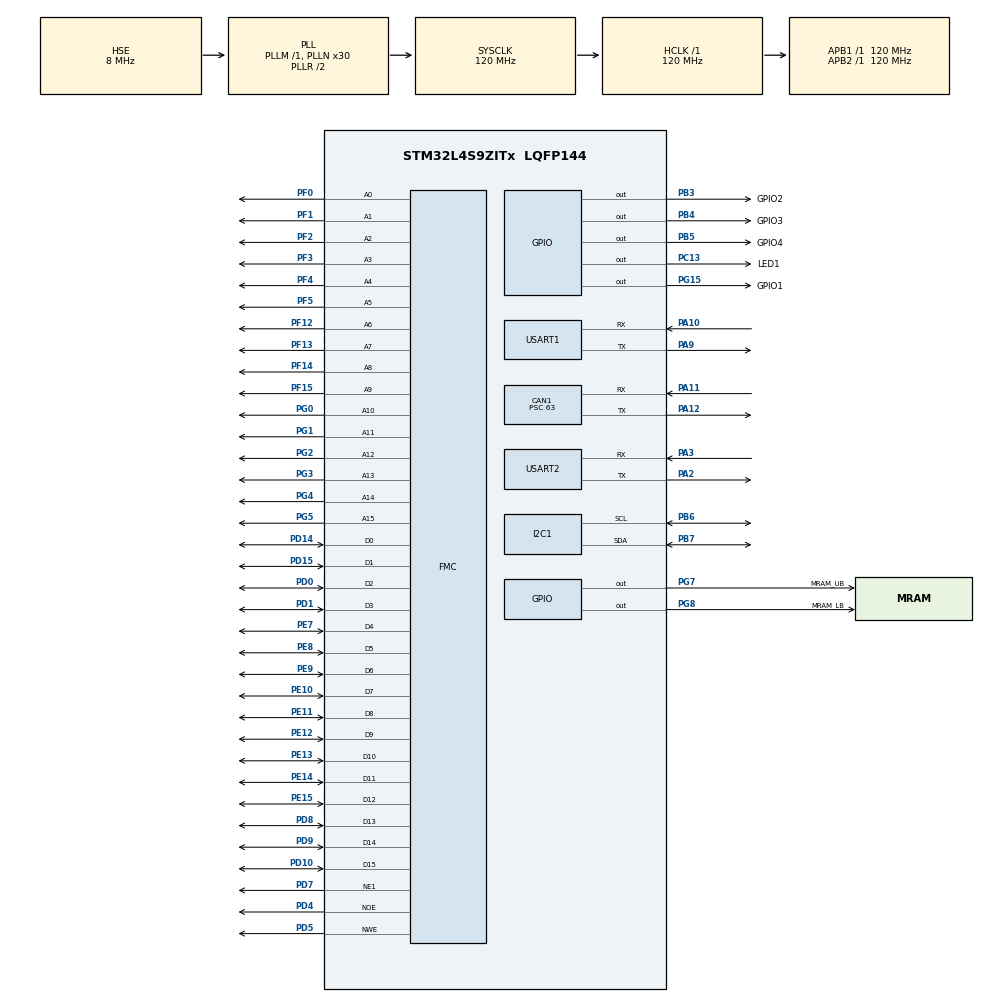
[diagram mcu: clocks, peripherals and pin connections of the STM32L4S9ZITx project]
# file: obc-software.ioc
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CAN1.BS1=CAN_BS1_1TQ
CAN1.BS2=CAN_BS2_1TQ
CAN1.CalculateTimeQuantum=525.0
CAN1.Prescaler=63
FMC.WriteFifo1=FMC_WRITE_FIFO_DISABLE
FMC.WriteOperation1=FMC_WRITE_OPERATION_ENABLE
I2C1.Timing=0x307075B1
Mcu.Family=STM32L4
Mcu.Name=STM32L4S9ZITx
Mcu.Package=LQFP144
NVIC.PriorityGroup=NVIC_PRIORITYGROUP_4
PA10.Mode=Asynchronous
PA10.Signal=USART1_RX
PA11.Mode=Master
PA11.Signal=CAN1_RX
PA12.Mode=Master
PA12.Signal=CAN1_TX
PA13\ (JTMS/SWDIO).Mode=Serial_Wire
PA13\ (JTMS/SWDIO).Signal=SYS_JTMS-SWDIO
PA14\ (JTCK/SWCLK).Mode=Serial_Wire
PA14\ (JTCK/SWCLK).Signal=SYS_JTCK-SWCLK
PA2.Mode=Asynchronous
PA2.Signal=USART2_TX
PA3.Mode=Asynchronous
PA3.Signal=USART2_RX
PA9.Mode=Asynchronous
PA9.Signal=USART1_TX
PB3\ (JTDO/TRACESWO).GPIO_Label=GPIO2
PB3\ (JTDO/TRACESWO).Signal=GPIO_Output
PB4\ (NJTRST).GPIO_Label=GPIO3
PB4\ (NJTRST).Signal=GPIO_Output
PB5.GPIO_Label=GPIO4
PB5.Signal=GPIO_Output
PB6.Mode=I2C
PB6.Signal=I2C1_SCL
PB7.Mode=I2C
PB7.Signal=I2C1_SDA
PC13.GPIO_Label=LED1
PC13.Signal=GPIO_Output
PD0.Signal=FMC_D2_DA2
PD1.Signal=FMC_D3_DA3
PD10.Signal=FMC_D15_DA15
PD14.Signal=FMC_D0_DA0
PD15.Signal=FMC_D1_DA1
PD4.Signal=FMC_NOE
PD5.Signal=FMC_NWE
PD7.Mode=NorPsramChipSelect1_1
PD7.Signal=FMC_NE1
PD8.Signal=FMC_D13_DA13
PD9.Signal=FMC_D14_DA14
PE10.Signal=FMC_D7_DA7
PE11.Signal=FMC_D8_DA8
PE12.Signal=FMC_D9_DA9
PE13.Signal=FMC_D10_DA10
PE14.Signal=FMC_D11_DA11
PE15.Signal=FMC_D12_DA12
PE7.Signal=FMC_D4_DA4
PE8.Signal=FMC_D5_DA5
PE9.Signal=FMC_D6_DA6
PF0.Signal=FMC_A0
PF1.Signal=FMC_A1
PF12.Signal=FMC_A6
PF13.Signal=FMC_A7
PF14.Signal=FMC_A8
PF15.Signal=FMC_A9
PF2.Signal=FMC_A2
PF3.Signal=FMC_A3
PF4.Signal=FMC_A4
PF5.Signal=FMC_A5
PG0.Signal=FMC_A10
PG1.Signal=FMC_A11
PG15.GPIO_Label=GPIO1
PG15.Signal=GPIO_Output
PG2.Signal=FMC_A12
PG3.Signal=FMC_A13
PG4.Signal=FMC_A14
PG5.Signal=FMC_A15
PG7.GPIO_Label=MRAM_UB
PG7.Signal=GPIO_Output
PG8.GPIO_Label=MRAM_LB
PG8.Signal=GPIO_Output
PH0-OSC_IN\ (PH0).Mode=HSE-External-Oscillator
PH0-OSC_IN\ (PH0).Signal=RCC_OSC_IN
PH1-OSC_OUT\ (PH1).Mode=HSE-External-Oscillator
PH1-OSC_OUT\ (PH1).Signal=RCC_OSC_OUT
ProjectManager.HeapSize=0x200
ProjectManager.StackSize=0x400
ProjectManager.TargetToolchain=SW4STM32
RCC.ADCFreq_Value=32000000
RCC.AHBFreq_Value=120000000
RCC.APB1Freq_Value=120000000
RCC.APB1TimFreq_Value=120000000
RCC.APB2Freq_Value=120000000
RCC.APB2TimFreq_Value=120000000
RCC.CortexFreq_Value=120000000
RCC.HCLKFreq_Value=120000000
RCC.HSE_VALUE=8000000
RCC.HSI48_VALUE=48000000
RCC.HSI_VALUE=16000000
RCC.LSE_VALUE=32768
RCC.MSI_VALUE=4000000
RCC.PLLN=30
RCC.PLLSourceVirtual=RCC_PLLSOURCE_HSE
RCC.SYSCLKFreq_VALUE=120000000
RCC.SYSCLKSource=RCC_SYSCLKSOURCE_PLLCLK
RCC.USBFreq_Value=32000000
RCC.VCOOutputFreq_Value=240000000
SH.FMC_A0.0=FMC_A0,16b-a1
SH.FMC_A1.0=FMC_A1,16b-a1
SH.FMC_A10.0=FMC_A10,16b-a1
SH.FMC_A11.0=FMC_A11,16b-a1
SH.FMC_A12.0=FMC_A12,16b-a1
SH.FMC_A13.0=FMC_A13,16b-a1
SH.FMC_A14.0=FMC_A14,16b-a1
SH.FMC_A15.0=FMC_A15,16b-a1
SH.FMC_A2.0=FMC_A2,16b-a1
SH.FMC_A3.0=FMC_A3,16b-a1
SH.FMC_A4.0=FMC_A4,16b-a1
SH.FMC_A5.0=FMC_A5,16b-a1
SH.FMC_A6.0=FMC_A6,16b-a1
SH.FMC_A7.0=FMC_A7,16b-a1
SH.FMC_A8.0=FMC_A8,16b-a1
SH.FMC_A9.0=FMC_A9,16b-a1
SH.FMC_D0_DA0.0=FMC_D0,16b-d1
SH.FMC_D10_DA10.0=FMC_D10,16b-d1
SH.FMC_D11_DA11.0=FMC_D11,16b-d1
SH.FMC_D12_DA12.0=FMC_D12,16b-d1
SH.FMC_D13_DA13.0=FMC_D13,16b-d1
SH.FMC_D14_DA14.0=FMC_D14,16b-d1
SH.FMC_D15_DA15.0=FMC_D15,16b-d1
SH.FMC_D1_DA1.0=FMC_D1,16b-d1
SH.FMC_D2_DA2.0=FMC_D2,16b-d1
SH.FMC_D3_DA3.0=FMC_D3,16b-d1
SH.FMC_D4_DA4.0=FMC_D4,16b-d1
SH.FMC_D5_DA5.0=FMC_D5,16b-d1
SH.FMC_D6_DA6.0=FMC_D6,16b-d1
SH.FMC_D7_DA7.0=FMC_D7,16b-d1
SH.FMC_D8_DA8.0=FMC_D8,16b-d1
SH.FMC_D9_DA9.0=FMC_D9,16b-d1
SH.FMC_NOE.0=FMC_NOE,Sram1
SH.FMC_NWE.0=FMC_NWE,Sram1
USART1.VirtualMode-Asynchronous=VM_ASYNC
USART2.VirtualMode-Asynchronous=VM_ASYNC
board=custom

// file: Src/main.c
/* USER CODE BEGIN Header */
/**
  ******************************************************************************
  * @file           : main.c
  * @brief          : Main program body
  ******************************************************************************
  * @attention
  *
  * <h2><center>&copy; Copyright (c) 2019 STMicroelectronics.
  * All rights reserved.</center></h2>
  *
  * This software component is licensed by ST under BSD 3-Clause license,
  * the "License"; You may not use this file except in compliance with the
  * License. You may obtain a copy of the License at:
  *                        opensource.org/licenses/BSD-3-Clause
  *
  ******************************************************************************
  */
/* USER CODE END Header */

#include "main.h"

/* USER CODE BEGIN Includes */
#include "string.h"
/* USER CODE END Includes */

CAN_HandleTypeDef hcan1;

I2C_HandleTypeDef hi2c1;

UART_HandleTypeDef huart1;
UART_HandleTypeDef huart2;

SRAM_HandleTypeDef hsram1;

/* USER CODE BEGIN PV */
volatile __attribute__((section (".mram"))) char mramData[150];
/* USER CODE END PV */

void SystemClock_Config(void);
static void MX_GPIO_Init(void);
static void MX_USART1_UART_Init(void);
static void MX_CAN1_Init(void);
static void MX_FMC_Init(void);
static void MX_I2C1_Init(void);
static void MX_USART2_UART_Init(void);

int main(void)
{

  /* MCU Configuration--------------------------------------------------------*/

  /* Reset of all peripherals, Initializes the Flash interface and the Systick. */
  HAL_Init();

  /* Configure the system clock */
  SystemClock_Config();

  /* Initialize all configured peripherals */
  MX_GPIO_Init();
  MX_USART1_UART_Init();
  MX_CAN1_Init();
  MX_FMC_Init();
  MX_I2C1_Init();
  MX_USART2_UART_Init();
  /* USER CODE BEGIN 2 */
    HAL_SRAM_WriteOperation_Enable(&hsram1);
  /* USER CODE END 2 */

  /* Infinite loop */
  /* USER CODE BEGIN WHILE */
  main_cpp();
    /* USER CODE END WHILE */

}

void SystemClock_Config(void)
{
  RCC_OscInitTypeDef RCC_OscInitStruct = {0};
  RCC_ClkInitTypeDef RCC_ClkInitStruct = {0};
  RCC_PeriphCLKInitTypeDef PeriphClkInit = {0};

  /** Configure the main internal regulator output voltage
  */
  if (HAL_PWREx_ControlVoltageScaling(PWR_REGULATOR_VOLTAGE_SCALE1_BOOST) != HAL_OK)
  {
    Error_Handler();
  }
  /** Initializes the CPU, AHB and APB busses clocks
  */
  RCC_OscInitStruct.OscillatorType = RCC_OSCILLATORTYPE_HSE;
  RCC_OscInitStruct.HSEState = RCC_HSE_ON;
  RCC_OscInitStruct.PLL.PLLState = RCC_PLL_ON;
  RCC_OscInitStruct.PLL.PLLSource = RCC_PLLSOURCE_HSE;
  RCC_OscInitStruct.PLL.PLLM = 1;
  RCC_OscInitStruct.PLL.PLLN = 30;
  RCC_OscInitStruct.PLL.PLLP = RCC_PLLP_DIV2;
  RCC_OscInitStruct.PLL.PLLQ = RCC_PLLQ_DIV2;
  RCC_OscInitStruct.PLL.PLLR = RCC_PLLR_DIV2;
  if (HAL_RCC_OscConfig(&RCC_OscInitStruct) != HAL_OK)
  {
    Error_Handler();
  }
  /** Initializes the CPU, AHB and APB busses clocks
  */
  RCC_ClkInitStruct.ClockType = RCC_CLOCKTYPE_HCLK|RCC_CLOCKTYPE_SYSCLK
                              |RCC_CLOCKTYPE_PCLK1|RCC_CLOCKTYPE_PCLK2;
  RCC_ClkInitStruct.SYSCLKSource = RCC_SYSCLKSOURCE_PLLCLK;
  RCC_ClkInitStruct.AHBCLKDivider = RCC_SYSCLK_DIV1;
  RCC_ClkInitStruct.APB1CLKDivider = RCC_HCLK_DIV1;
  RCC_ClkInitStruct.APB2CLKDivider = RCC_HCLK_DIV1;

  if (HAL_RCC_ClockConfig(&RCC_ClkInitStruct, FLASH_LATENCY_5) != HAL_OK)
  {
    Error_Handler();
  }
  PeriphClkInit.PeriphClockSelection = RCC_PERIPHCLK_USART1|RCC_PERIPHCLK_USART2
                              |RCC_PERIPHCLK_I2C1;
  PeriphClkInit.Usart1ClockSelection = RCC_USART1CLKSOURCE_PCLK2;
  PeriphClkInit.Usart2ClockSelection = RCC_USART2CLKSOURCE_PCLK1;
  PeriphClkInit.I2c1ClockSelection = RCC_I2C1CLKSOURCE_PCLK1;
  if (HAL_RCCEx_PeriphCLKConfig(&PeriphClkInit) != HAL_OK)
  {
    Error_Handler();
  }
}

static void MX_CAN1_Init(void)
{

  hcan1.Instance = CAN1;
  hcan1.Init.Prescaler = 63;
  hcan1.Init.Mode = CAN_MODE_NORMAL;
  hcan1.Init.SyncJumpWidth = CAN_SJW_1TQ;
  hcan1.Init.TimeSeg1 = CAN_BS1_1TQ;
  hcan1.Init.TimeSeg2 = CAN_BS2_1TQ;
  hcan1.Init.TimeTriggeredMode = DISABLE;
  hcan1.Init.AutoBusOff = DISABLE;
  hcan1.Init.AutoWakeUp = DISABLE;
  hcan1.Init.AutoRetransmission = DISABLE;
  hcan1.Init.ReceiveFifoLocked = DISABLE;
  hcan1.Init.TransmitFifoPriority = DISABLE;
  if (HAL_CAN_Init(&hcan1) != HAL_OK)
  {
    Error_Handler();
  }

}

static void MX_I2C1_Init(void)
{

  hi2c1.Instance = I2C1;
  hi2c1.Init.Timing = 0x307075B1;
  hi2c1.Init.OwnAddress1 = 0;
  hi2c1.Init.AddressingMode = I2C_ADDRESSINGMODE_7BIT;
  hi2c1.Init.DualAddressMode = I2C_DUALADDRESS_DISABLE;
  hi2c1.Init.OwnAddress2 = 0;
  hi2c1.Init.OwnAddress2Masks = I2C_OA2_NOMASK;
  hi2c1.Init.GeneralCallMode = I2C_GENERALCALL_DISABLE;
  hi2c1.Init.NoStretchMode = I2C_NOSTRETCH_DISABLE;
  if (HAL_I2C_Init(&hi2c1) != HAL_OK)
  {
    Error_Handler();
  }
  /** Configure Analogue filter
  */
  if (HAL_I2CEx_ConfigAnalogFilter(&hi2c1, I2C_ANALOGFILTER_ENABLE) != HAL_OK)
  {
    Error_Handler();
  }
  /** Configure Digital filter
  */
  if (HAL_I2CEx_ConfigDigitalFilter(&hi2c1, 0) != HAL_OK)
  {
    Error_Handler();
  }

}

static void MX_USART1_UART_Init(void)
{

  huart1.Instance = USART1;
  huart1.Init.BaudRate = 115200;
  huart1.Init.WordLength = UART_WORDLENGTH_8B;
  huart1.Init.StopBits = UART_STOPBITS_1;
  huart1.Init.Parity = UART_PARITY_NONE;
  huart1.Init.Mode = UART_MODE_TX_RX;
  huart1.Init.HwFlowCtl = UART_HWCONTROL_NONE;
  huart1.Init.OverSampling = UART_OVERSAMPLING_16;
  huart1.Init.OneBitSampling = UART_ONE_BIT_SAMPLE_DISABLE;
  huart1.Init.ClockPrescaler = UART_PRESCALER_DIV1;
  huart1.AdvancedInit.AdvFeatureInit = UART_ADVFEATURE_NO_INIT;
  if (HAL_UART_Init(&huart1) != HAL_OK)
  {
    Error_Handler();
  }
  if (HAL_UARTEx_SetTxFifoThreshold(&huart1, UART_TXFIFO_THRESHOLD_1_8) != HAL_OK)
  {
    Error_Handler();
  }
  if (HAL_UARTEx_SetRxFifoThreshold(&huart1, UART_RXFIFO_THRESHOLD_1_8) != HAL_OK)
  {
    Error_Handler();
  }
  if (HAL_UARTEx_DisableFifoMode(&huart1) != HAL_OK)
  {
    Error_Handler();
  }

}

static void MX_USART2_UART_Init(void)
{

  huart2.Instance = USART2;
  huart2.Init.BaudRate = 115200;
  huart2.Init.WordLength = UART_WORDLENGTH_8B;
  huart2.Init.StopBits = UART_STOPBITS_1;
  huart2.Init.Parity = UART_PARITY_NONE;
  huart2.Init.Mode = UART_MODE_TX_RX;
  huart2.Init.HwFlowCtl = UART_HWCONTROL_NONE;
  huart2.Init.OverSampling = UART_OVERSAMPLING_16;
  huart2.Init.OneBitSampling = UART_ONE_BIT_SAMPLE_DISABLE;
  huart2.Init.ClockPrescaler = UART_PRESCALER_DIV1;
  huart2.AdvancedInit.AdvFeatureInit = UART_ADVFEATURE_NO_INIT;
  if (HAL_UART_Init(&huart2) != HAL_OK)
  {
    Error_Handler();
  }
  if (HAL_UARTEx_SetTxFifoThreshold(&huart2, UART_TXFIFO_THRESHOLD_1_8) != HAL_OK)
  {
    Error_Handler();
  }
  if (HAL_UARTEx_SetRxFifoThreshold(&huart2, UART_RXFIFO_THRESHOLD_1_8) != HAL_OK)
  {
    Error_Handler();
  }
  if (HAL_UARTEx_DisableFifoMode(&huart2) != HAL_OK)
  {
    Error_Handler();
  }

}

/* FMC initialization function */
static void MX_FMC_Init(void)
{

  FMC_NORSRAM_TimingTypeDef Timing = {0};

  /** Perform the SRAM1 memory initialization sequence
  */
  hsram1.Instance = FMC_NORSRAM_DEVICE;
  hsram1.Extended = FMC_NORSRAM_EXTENDED_DEVICE;
  /* hsram1.Init */
  hsram1.Init.NSBank = FMC_NORSRAM_BANK1;
  hsram1.Init.DataAddressMux = FMC_DATA_ADDRESS_MUX_DISABLE;
  hsram1.Init.MemoryType = FMC_MEMORY_TYPE_SRAM;
  hsram1.Init.MemoryDataWidth = FMC_NORSRAM_MEM_BUS_WIDTH_16;
  hsram1.Init.BurstAccessMode = FMC_BURST_ACCESS_MODE_DISABLE;
  hsram1.Init.WaitSignalPolarity = FMC_WAIT_SIGNAL_POLARITY_LOW;
  hsram1.Init.WaitSignalActive = FMC_WAIT_TIMING_BEFORE_WS;
  hsram1.Init.WriteOperation = FMC_WRITE_OPERATION_ENABLE;
  hsram1.Init.WaitSignal = FMC_WAIT_SIGNAL_DISABLE;
  hsram1.Init.ExtendedMode = FMC_EXTENDED_MODE_DISABLE;
  hsram1.Init.AsynchronousWait = FMC_ASYNCHRONOUS_WAIT_DISABLE;
  hsram1.Init.WriteBurst = FMC_WRITE_BURST_DISABLE;
  hsram1.Init.ContinuousClock = FMC_CONTINUOUS_CLOCK_SYNC_ONLY;
  hsram1.Init.WriteFifo = FMC_WRITE_FIFO_DISABLE;
  hsram1.Init.NBLSetupTime = 0;
  hsram1.Init.PageSize = FMC_PAGE_SIZE_NONE;
  /* Timing */
  Timing.AddressSetupTime = 15;
  Timing.AddressHoldTime = 15;
  Timing.DataSetupTime = 255;
  Timing.DataHoldTime = 0;
  Timing.BusTurnAroundDuration = 15;
  Timing.CLKDivision = 16;
  Timing.DataLatency = 17;
  Timing.AccessMode = FMC_ACCESS_MODE_A;
  /* ExtTiming */

  if (HAL_SRAM_Init(&hsram1, &Timing, NULL) != HAL_OK)
  {
    Error_Handler( );
  }

}

static void MX_GPIO_Init(void)
{
  GPIO_InitTypeDef GPIO_InitStruct = {0};

  /* GPIO Ports Clock Enable */
  __HAL_RCC_GPIOC_CLK_ENABLE();
  __HAL_RCC_GPIOF_CLK_ENABLE();
  __HAL_RCC_GPIOH_CLK_ENABLE();
  __HAL_RCC_GPIOA_CLK_ENABLE();
  __HAL_RCC_GPIOG_CLK_ENABLE();
  __HAL_RCC_GPIOE_CLK_ENABLE();
  __HAL_RCC_GPIOD_CLK_ENABLE();
  HAL_PWREx_EnableVddIO2();
  __HAL_RCC_GPIOB_CLK_ENABLE();

  /*Configure GPIO pin Output Level */
  HAL_GPIO_WritePin(LED1_GPIO_Port, LED1_Pin, GPIO_PIN_RESET);

  /*Configure GPIO pin Output Level */
  HAL_GPIO_WritePin(GPIOG, MRAM_UB_Pin|MRAM_LB_Pin|GPIO1_Pin, GPIO_PIN_RESET);

  /*Configure GPIO pin Output Level */
  HAL_GPIO_WritePin(GPIOB, GPIO2_Pin|GPIO3_Pin|GPIO4_Pin, GPIO_PIN_RESET);

  /*Configure GPIO pin : LED1_Pin */
  GPIO_InitStruct.Pin = LED1_Pin;
  GPIO_InitStruct.Mode = GPIO_MODE_OUTPUT_PP;
  GPIO_InitStruct.Pull = GPIO_NOPULL;
  GPIO_InitStruct.Speed = GPIO_SPEED_FREQ_LOW;
  HAL_GPIO_Init(LED1_GPIO_Port, &GPIO_InitStruct);

  /*Configure GPIO pins : MRAM_UB_Pin MRAM_LB_Pin GPIO1_Pin */
  GPIO_InitStruct.Pin = MRAM_UB_Pin|MRAM_LB_Pin|GPIO1_Pin;
  GPIO_InitStruct.Mode = GPIO_MODE_OUTPUT_PP;
  GPIO_InitStruct.Pull = GPIO_NOPULL;
  GPIO_InitStruct.Speed = GPIO_SPEED_FREQ_LOW;
  HAL_GPIO_Init(GPIOG, &GPIO_InitStruct);

  /*Configure GPIO pins : GPIO2_Pin GPIO3_Pin GPIO4_Pin */
  GPIO_InitStruct.Pin = GPIO2_Pin|GPIO3_Pin|GPIO4_Pin;
  GPIO_InitStruct.Mode = GPIO_MODE_OUTPUT_PP;
  GPIO_InitStruct.Pull = GPIO_NOPULL;
  GPIO_InitStruct.Speed = GPIO_SPEED_FREQ_LOW;
  HAL_GPIO_Init(GPIOB, &GPIO_InitStruct);

}

void Error_Handler(void)
{
}

/************************ (C) COPYRIGHT STMicroelectronics *****END OF FILE****/
